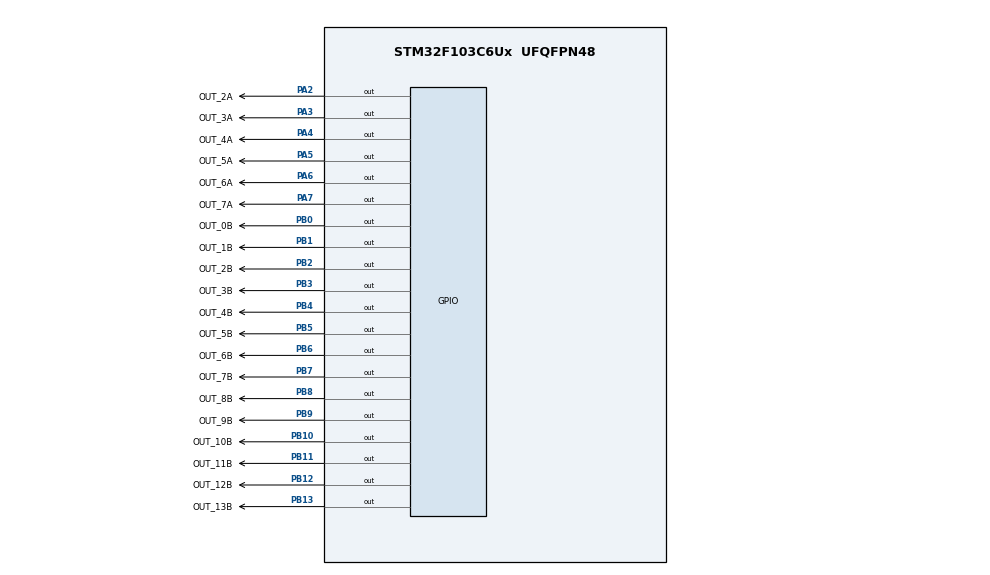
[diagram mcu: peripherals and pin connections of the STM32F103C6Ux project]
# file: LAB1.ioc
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Mcu.Family=STM32F1
Mcu.Name=STM32F103C6Ux
Mcu.Package=UFQFPN48
NVIC.PriorityGroup=NVIC_PRIORITYGROUP_4
PA2.GPIO_Label=OUT_2A
PA2.Signal=GPIO_Output
PA3.GPIO_Label=OUT_3A
PA3.Signal=GPIO_Output
PA4.GPIO_Label=OUT_4A
PA4.Signal=GPIO_Output
PA5.GPIO_Label=OUT_5A
PA5.Signal=GPIO_Output
PA6.GPIO_Label=OUT_6A
PA6.Signal=GPIO_Output
PA7.GPIO_Label=OUT_7A
PA7.Signal=GPIO_Output
PB0.GPIO_Label=OUT_0B
PB0.Signal=GPIO_Output
PB1.GPIO_Label=OUT_1B
PB1.Signal=GPIO_Output
PB10.GPIO_Label=OUT_10B
PB10.Signal=GPIO_Output
PB11.GPIO_Label=OUT_11B
PB11.Signal=GPIO_Output
PB12.GPIO_Label=OUT_12B
PB12.Signal=GPIO_Output
PB13.GPIO_Label=OUT_13B
PB13.Signal=GPIO_Output
PB2.GPIO_Label=OUT_2B
PB2.Signal=GPIO_Output
PB3.GPIO_Label=OUT_3B
PB3.Signal=GPIO_Output
PB4.GPIO_Label=OUT_4B
PB4.Signal=GPIO_Output
PB5.GPIO_Label=OUT_5B
PB5.Signal=GPIO_Output
PB6.GPIO_Label=OUT_6B
PB6.Signal=GPIO_Output
PB7.GPIO_Label=OUT_7B
PB7.Signal=GPIO_Output
PB8.GPIO_Label=OUT_8B
PB8.Signal=GPIO_Output
PB9.GPIO_Label=OUT_9B
PB9.Signal=GPIO_Output
ProjectManager.HeapSize=0x200
ProjectManager.StackSize=0x400
ProjectManager.TargetToolchain=STM32CubeIDE
RCC.APB1Freq_Value=8000000
RCC.APB2Freq_Value=8000000
board=custom

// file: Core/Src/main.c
/* USER CODE BEGIN Header */
/**
  ******************************************************************************
  * @file           : main.c
  * @brief          : Main program body
  ******************************************************************************
  * @attention
  *
  * Copyright (c) 2024 STMicroelectronics.
  * All rights reserved.
  *
  * This software is licensed under terms that can be found in the LICENSE file
  * in the root directory of this software component.
  * If no LICENSE file comes with this software, it is provided AS-IS.
  *
  ******************************************************************************
  */
/* USER CODE END Header */
#include "main.h"

/* USER CODE BEGIN Includes */
#include "LAB1_EX0.h"
//#include "LAB1_EX1.h"
//#include "LAB1_EX2.h"
//#include "LAB1_EX3.h"
//#include "LAB1_EX4.h"
//#include "LAB1_EX5.h"
#include "LAB1_EX6.h"
/* USER CODE END Includes */

void SystemClock_Config(void);
static void MX_GPIO_Init(void);

int main(void)
{

  /* MCU Configuration--------------------------------------------------------*/

  /* Reset of all peripherals, Initializes the Flash interface and the Systick. */
  HAL_Init();

  /* Configure the system clock */
  SystemClock_Config();

  /* Initialize all configured peripherals */
  MX_GPIO_Init();

  /* Infinite loop */
  /* USER CODE BEGIN WHILE */
  GPIO_INIT_LAB1_EX0();
  //GPIO_INIT_LAB1_EX1();
  //GPIO_INIT_LAB1_EX2();
  //GPIO_INIT_LAB1_EX3();
  //GPIO_INIT_LAB1_EX4();
  //GPIO_INIT_LAB1_EX5();
  //GPIO_INIT_LAB1_EX6();
  //GPIO_INIT_LAB1_EX7();
  GPIO_INIT_LAB1_EX10(11, 49, 45); // 11h 49m 45s
  while (1)
  {
	 EXECUTE_LAB1_EX0();
	 //EXECUTE_LAB1_EX1();
	 //EXECUTE_LAB1_EX2();
	 //EXECUTE_LAB1_EX3();
	 //EXECUTE_LAB1_EX4();
	 //EXECUTE_LAB1_EX5();
	 //EXECUTE_LAB1_EX6();
	 //EXECUTE_LAB1_EX6();
	 //EXECUTE_LAB1_EX7();
	 EXECUTE_LAB1_EX10();
	 HAL_Delay(1000);
    /* USER CODE END WHILE */

  }
}

void SystemClock_Config(void)
{
  RCC_OscInitTypeDef RCC_OscInitStruct = {0};
  RCC_ClkInitTypeDef RCC_ClkInitStruct = {0};

  /** Initializes the RCC Oscillators according to the specified parameters
  * in the RCC_OscInitTypeDef structure.
  */
  RCC_OscInitStruct.OscillatorType = RCC_OSCILLATORTYPE_HSI;
  RCC_OscInitStruct.HSIState = RCC_HSI_ON;
  RCC_OscInitStruct.HSICalibrationValue = RCC_HSICALIBRATION_DEFAULT;
  RCC_OscInitStruct.PLL.PLLState = RCC_PLL_NONE;
  if (HAL_RCC_OscConfig(&RCC_OscInitStruct) != HAL_OK)
  {
    Error_Handler();
  }

  /** Initializes the CPU, AHB and APB buses clocks
  */
  RCC_ClkInitStruct.ClockType = RCC_CLOCKTYPE_HCLK|RCC_CLOCKTYPE_SYSCLK
                              |RCC_CLOCKTYPE_PCLK1|RCC_CLOCKTYPE_PCLK2;
  RCC_ClkInitStruct.SYSCLKSource = RCC_SYSCLKSOURCE_HSI;
  RCC_ClkInitStruct.AHBCLKDivider = RCC_SYSCLK_DIV1;
  RCC_ClkInitStruct.APB1CLKDivider = RCC_HCLK_DIV1;
  RCC_ClkInitStruct.APB2CLKDivider = RCC_HCLK_DIV1;

  if (HAL_RCC_ClockConfig(&RCC_ClkInitStruct, FLASH_LATENCY_0) != HAL_OK)
  {
    Error_Handler();
  }
}

static void MX_GPIO_Init(void)
{
  GPIO_InitTypeDef GPIO_InitStruct = {0};

  /* GPIO Ports Clock Enable */
  __HAL_RCC_GPIOA_CLK_ENABLE();
  __HAL_RCC_GPIOB_CLK_ENABLE();

  /*Configure GPIO pin Output Level */
  HAL_GPIO_WritePin(GPIOA, OUT_2A_Pin|OUT_3A_Pin|OUT_4A_Pin|OUT_5A_Pin
                          |OUT_6A_Pin|OUT_7A_Pin, GPIO_PIN_RESET);

  /*Configure GPIO pin Output Level */
  HAL_GPIO_WritePin(GPIOB, OUT_0B_Pin|OUT_1B_Pin|OUT_2B_Pin|OUT_10B_Pin
                          |OUT_11B_Pin|OUT_12B_Pin|OUT_13B_Pin|OUT_3B_Pin
                          |OUT_4B_Pin|OUT_5B_Pin|OUT_6B_Pin|OUT_7B_Pin
                          |OUT_8B_Pin|OUT_9B_Pin, GPIO_PIN_RESET);

  /*Configure GPIO pins : OUT_2A_Pin OUT_3A_Pin OUT_4A_Pin OUT_5A_Pin
                           OUT_6A_Pin OUT_7A_Pin */
  GPIO_InitStruct.Pin = OUT_2A_Pin|OUT_3A_Pin|OUT_4A_Pin|OUT_5A_Pin
                          |OUT_6A_Pin|OUT_7A_Pin;
  GPIO_InitStruct.Mode = GPIO_MODE_OUTPUT_PP;
  GPIO_InitStruct.Pull = GPIO_NOPULL;
  GPIO_InitStruct.Speed = GPIO_SPEED_FREQ_LOW;
  HAL_GPIO_Init(GPIOA, &GPIO_InitStruct);

  /*Configure GPIO pins : OUT_0B_Pin OUT_1B_Pin OUT_2B_Pin OUT_10B_Pin
                           OUT_11B_Pin OUT_12B_Pin OUT_13B_Pin OUT_3B_Pin
                           OUT_4B_Pin OUT_5B_Pin OUT_6B_Pin OUT_7B_Pin
                           OUT_8B_Pin OUT_9B_Pin */
  GPIO_InitStruct.Pin = OUT_0B_Pin|OUT_1B_Pin|OUT_2B_Pin|OUT_10B_Pin
                          |OUT_11B_Pin|OUT_12B_Pin|OUT_13B_Pin|OUT_3B_Pin
                          |OUT_4B_Pin|OUT_5B_Pin|OUT_6B_Pin|OUT_7B_Pin
                          |OUT_8B_Pin|OUT_9B_Pin;
  GPIO_InitStruct.Mode = GPIO_MODE_OUTPUT_PP;
  GPIO_InitStruct.Pull = GPIO_NOPULL;
  GPIO_InitStruct.Speed = GPIO_SPEED_FREQ_LOW;
  HAL_GPIO_Init(GPIOB, &GPIO_InitStruct);

}

void Error_Handler(void)
{
  __disable_irq();
  while (1)
  {
  }
}
